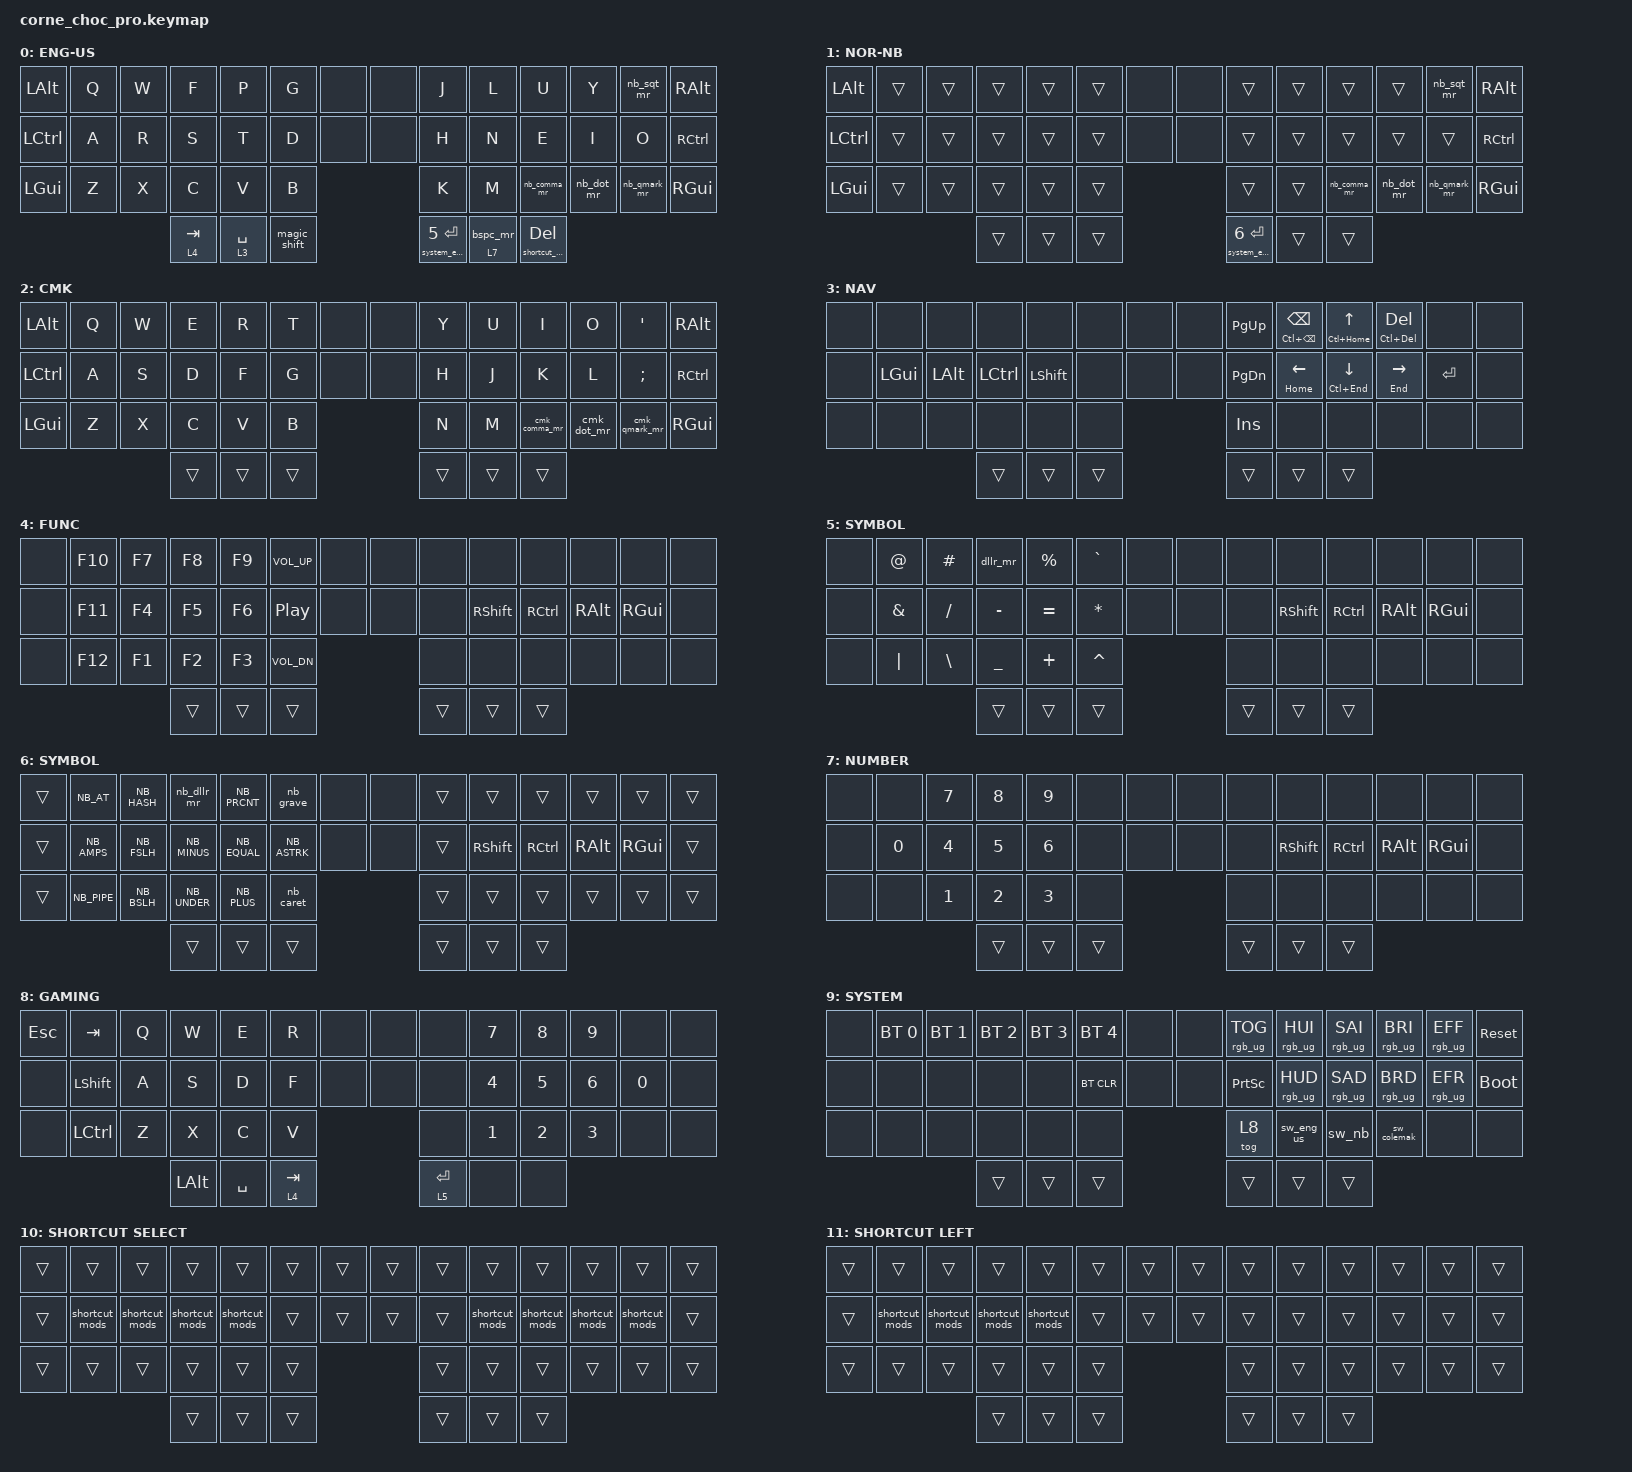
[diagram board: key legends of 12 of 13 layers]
/*
 * Copyright (c) 2020 The ZMK Contributors
 *
 * SPDX-License-Identifier: MIT
 */

#include <behaviors.dtsi>
#include <dt-bindings/zmk/keys.h>
#include <dt-bindings/zmk/bt.h>
#include <dt-bindings/zmk/rgb.h>

#include <behaviors/unicode.dtsi>  // Source header for this module
#include <zmk-helpers/helper.h>
#include <locale/keys_nb.h>

/* Corne Choc Pro 46-key position map (encoder buttons at 6, 7, 20, 21)
 * ╭───────────────────────────────╮ ╭───────────────────────────────╮
 * │ [0]   1   2   3   4   5  [6]  │ │  [7]  8   9  10  11  12  [13] │
 * │ [14] 15  16  17  18  19  [20] │ │ [21] 22  23  24  25  26  [27] │
 * │ [28] 29  30  31  32  33       │ │      34  35  36  37  38  [39] │
 * ╰────────────────╮ 40  41  42   │ │      43  44  45 ╭─────────────╯
 *                  ╰──────────────╯ ╰─────────────────╯              */
#define XXX &none
#define ___ &trans

/* Thumb layer-tap: hold = momentary layer, tap = keypress */
ZMK_HOLD_TAP(tlt,
    flavor = "balanced";
    tapping-term-ms = <200>;
    quick-tap-ms = <175>;
    bindings = <&mo>, <&kp>;
)

/* Thumb layer-tap for backspace: hold = momentary layer, tap = bspc/del mod-morph */
ZMK_HOLD_TAP(tlt_bspc,
    flavor = "balanced";
    tapping-term-ms = <200>;
    quick-tap-ms = <175>;
    bindings = <&mo>, <&bspc_mr>;
)

/* Nav mod-tap: hold = navigation shortcut, tap = key, double-tap+hold = repeat */
ZMK_HOLD_TAP(nav_mt,
    flavor = "tap-preferred";
    tapping-term-ms = <200>;
    quick-tap-ms = <175>;
    bindings = <&kp>, <&kp>;
)

/* Tap Delete; hold to select a hand for home-row shortcut modifiers. */
ZMK_HOLD_TAP(delete_shortcuts,
    flavor = "hold-preferred";
    tapping-term-ms = <200>;
    bindings = <&shortcut_mods>, <&kp>;
)

// Switch to using to shift instead of holding it down to get the alt buttons (mod morph)
#define NAV_LEFT  &nav_mt HOME     LEFT  // Tap: left  | Long-tap: start of line.
#define NAV_RIGHT &nav_mt END      RIGHT // Tap: right | Long-tap: end   of line.
#define NAV_UP    &nav_mt LC(HOME) UP    // Tap: up    | Long-tap: start of doc.
#define NAV_DOWN  &nav_mt LC(END)  DOWN  // Tap: down  | Long-tap: end   of doc.
#define NAV_BSPC  &nav_mt LC(BSPC) BSPC  // Tap: bspc  | Long-tap: delete word bwd.
#define NAV_DEL   &nav_mt LC(DEL)  DEL   // Tap: del   | Long-tap: delete word fwd.

/* Backspace / Delete mod-morph: tap = Bspc, Shift + tap = Del */
ZMK_MOD_MORPH(bspc_mr,
    bindings = <&kp BSPC>, <&kp DEL>;
    mods = <(MOD_LSFT|MOD_RSFT)>;
)

/* Norwegian mod-morphs: same semantics as US versions but with NB_ keycodes */
ZMK_MOD_MORPH(nb_comma_mr,
    bindings = <&kp NB_COMMA>, <&kp NB_SEMI>;
    mods = <(MOD_LSFT|MOD_RSFT)>;
)
ZMK_MOD_MORPH(nb_dot_mr,
    bindings = <&kp NB_DOT>, <&kp NB_COLON>;
    mods = <(MOD_LSFT|MOD_RSFT)>;
)
ZMK_MOD_MORPH(nb_qmark_mr,
    bindings = <&kp NB_QMARK>, <&kp NB_EXCL>;
    mods = <(MOD_LSFT|MOD_RSFT)>;
)
ZMK_MOD_MORPH(nb_dllr_mr,
    bindings = <&kp NB_DLLR>, <&kp NB_EURO>;
    mods = <(MOD_LSFT|MOD_RSFT)>;
)
ZMK_MOD_MORPH(nb_sqt_mr,
    bindings = <&kp NB_SQT>, <&kp NB_DQT>;
    mods = <(MOD_LSFT|MOD_RSFT)>;
)

/* Colemak maps P to ; and SEMI to O, so use the host-layout key positions. */
ZMK_MOD_MORPH(cmk_comma_mr,
    bindings = <&kp COMMA>, <&kp P>;
    mods = <(MOD_LSFT|MOD_RSFT)>;
)
ZMK_MOD_MORPH(cmk_dot_mr,
    bindings = <&kp DOT>, <&kp LS(P)>;
    mods = <(MOD_LSFT|MOD_RSFT)>;
)
ZMK_MOD_MORPH(cmk_qmark_mr,
    bindings = <&kp LS(SLASH)>, <&kp EXCL>;
    mods = <(MOD_LSFT|MOD_RSFT)>;
)
/* Dead keys: send dead key + space so Windows outputs the literal character */
ZMK_MACRO(nb_grave,
    bindings = <&kp NB_GRAVE &kp SPACE>;
)
ZMK_MACRO(nb_caret,
    bindings = <&kp NB_CARET &kp SPACE>;
)

/* Euro sign via Windows Alt+numpad (Alt+0128) — works without WinCompose */
ZMK_MACRO(euro,
    bindings
        = <&macro_press &kp LALT>
        , <&macro_tap &kp KP_N0>
        , <&macro_tap &kp KP_N1>
        , <&macro_tap &kp KP_N2>
        , <&macro_tap &kp KP_N8>
        , <&macro_release &kp LALT>;
)

/* Layout switch macros — &to 0 clears all overlays, then &tog N activates the desired overlay */
ZMK_MACRO(sw_eng_us, bindings = <&to 0>;)
ZMK_MACRO(sw_nb,      bindings = <&to 0 &tog 1>;)
ZMK_MACRO(sw_colemak, bindings = <&to 0 &tog 2>;)

/* Dollar / Euro mod-morph: tap = $, Shift + tap = € */
ZMK_MOD_MORPH(dllr_mr,
    bindings = <&kp DLLR>, <&euro>;
    mods = <(MOD_LSFT|MOD_RSFT)>;
)

/ {
    chosen {
        zmk,physical-layout = &default_layout;
    };
};

/ {
    behaviors {
        /* Tap = one-shot Shift, hold = Shift, double-tap = Caps Lock. */
        magic_shift: magic_shift {
            compatible = "zmk,behavior-magic-shift";
            #binding-cells = <0>;
            hold-term-ms = <200>;
            double-tap-ms = <250>;
            one-shot-term-ms = <1000>;
            bindings = <&kp LSHFT>, <&kp CAPS>;
        };

        system_enter: system_enter {
            compatible = "zmk,behavior-system-enter";
            #binding-cells = <2>;
            bindings = <&mo>, <&kp>;
            system-layer = <&system_layer>;
            tapping-term-ms = <200>;
            system-chord-term-ms = <200>;
            first-non-thumb-position = <40>;
        };

        shortcut_mods: shortcut_mods {
            compatible = "zmk,behavior-shortcut-mods";
            #binding-cells = <0>;
            bindings = <&kp LGUI>, <&kp LALT>, <&kp LCTRL>, <&kp LSHFT>,
                       <&kp RSHFT>, <&kp RCTRL>, <&kp RALT>, <&kp RGUI>;
        };
    };
};

/ {
    combos {
        compatible = "zmk,combos";
        // Top-row adjacent pairs — positions from the 46-key map above
        // Left side:  2=W  3=F  4=P
        // Right side: 9=L  10=U  11=Y

        combo_esc  { timeout-ms = <50>; require-prior-idle-ms = <150>; key-positions = <1 2>;   bindings = <&kp ESC>; };

        combo_rbkt    { timeout-ms = <50>; require-prior-idle-ms = <150>; key-positions = <2 3>;   bindings = <&kp RBKT>;    layers = <0 2>; };
        combo_lbkt    { timeout-ms = <50>; require-prior-idle-ms = <150>; key-positions = <3 4>;   bindings = <&kp LBKT>;    layers = <0 2>; };
        combo_nb_rbkt { timeout-ms = <50>; require-prior-idle-ms = <150>; key-positions = <2 3>;   bindings = <&kp NB_RBKT>; layers = <1>; };
        combo_nb_lbkt { timeout-ms = <50>; require-prior-idle-ms = <150>; key-positions = <3 4>;   bindings = <&kp NB_LBKT>; layers = <1>; };
        
        combo_rbrc    { timeout-ms = <50>; require-prior-idle-ms = <150>; key-positions = <30 31>; bindings = <&kp RBRC>;    layers = <0 2>; };
        combo_lbrc    { timeout-ms = <50>; require-prior-idle-ms = <150>; key-positions = <31 32>; bindings = <&kp LBRC>;    layers = <0 2>; };
        combo_nb_rbrc { timeout-ms = <50>; require-prior-idle-ms = <150>; key-positions = <30 31>; bindings = <&kp NB_RBRC>; layers = <1>; };
        combo_nb_lbrc { timeout-ms = <50>; require-prior-idle-ms = <150>; key-positions = <31 32>; bindings = <&kp NB_LBRC>; layers = <1>; };
        
        combo_lpar    { timeout-ms = <50>; require-prior-idle-ms = <150>; key-positions = <9 10>;  bindings = <&kp LPAR>;    layers = <0 2>; };
        combo_rpar    { timeout-ms = <50>; require-prior-idle-ms = <150>; key-positions = <10 11>; bindings = <&kp RPAR>;    layers = <0 2>; };
        combo_nb_lpar { timeout-ms = <50>; require-prior-idle-ms = <150>; key-positions = <9 10>;  bindings = <&kp NB_LPAR>; layers = <1>; };
        combo_nb_rpar { timeout-ms = <50>; require-prior-idle-ms = <150>; key-positions = <10 11>; bindings = <&kp NB_RPAR>; layers = <1>; };
        
        combo_lt      { timeout-ms = <50>; require-prior-idle-ms = <150>; key-positions = <35 36>; bindings = <&kp LS(COMMA)>; layers = <0 2>; };
        combo_gt      { timeout-ms = <50>; require-prior-idle-ms = <150>; key-positions = <36 37>; bindings = <&kp LS(DOT)>;   layers = <0 2>; };
        combo_nb_lt   { timeout-ms = <50>; require-prior-idle-ms = <150>; key-positions = <35 36>; bindings = <&kp NB_LT>;   layers = <1>; };
        combo_nb_gt   { timeout-ms = <50>; require-prior-idle-ms = <150>; key-positions = <36 37>; bindings = <&kp NB_GT>;   layers = <1>; };
        
    };
};

/ {
    keymap {
        compatible = "zmk,keymap";

        colemak_layer {
            display-name = "ENG-US";
            bindings = <
            //╭─────────────┬─────────────┬─────────────┬─────────────┬─────────────┬─────────────╮         ╭─────────────┬─────────────┬─────────────┬─────────────┬─────────────┬─────────────╮
                &kp LALT      &kp Q         &kp W         &kp F         &kp P         &kp G         XXX XXX   &kp J         &kp L         &kp U         &kp Y         &nb_sqt_mr    &kp RALT
            //├─────────────┼─────────────┼─────────────┼─────────────┬─────────────┼─────────────┤         ├─────────────┬─────────────┼─────────────┼─────────────┼─────────────┼─────────────┤
                &kp LCTRL     &kp A         &kp R         &kp S         &kp T         &kp D         XXX XXX   &kp H         &kp N         &kp E         &kp I         &kp O         &kp RCTRL
            //├─────────────┼─────────────┼─────────────┼─────────────┬─────────────┼─────────────┤         ├─────────────┬─────────────┼─────────────┼─────────────┼─────────────┼─────────────┤
                &kp LGUI      &kp Z         &kp X         &kp C         &kp V         &kp B                   &kp K         &kp M         &nb_comma_mr  &nb_dot_mr    &nb_qmark_mr  &kp RGUI
            //╰─────────────┼─────────────┴─────────────┼─────────────┬─────────────┼─────────────┤         ├─────────────┬─────────────┼─────────────┼─────────────┴───────────────────────────╯
            //                                            MAGIC SHIFT   NAVIGATION    FUNCTION                SYMBOL        NUMBERS       DELETE
                                                          &tlt 4 TAB    &tlt 3 SPACE  &magic_shift          &system_enter 5 RET    &tlt_bspc 7 0 &delete_shortcuts 0 DEL
            //                                          ╰─────────────┴─────────────┴─────────────╯         ╰─────────────┴─────────────┴─────────────╯
            >;
        };

        // - NORWEGIAN OVERLAY LAYERS (below all momentary layers so they don't shadow the display name) ---------------------------------

        nb_layer {
            display-name = "NOR-NB";
            bindings = <
            //╭─────────────┬─────────────┬─────────────┬─────────────┬─────────────┬─────────────╮         ╭─────────────┬─────────────┬─────────────┬─────────────┬─────────────┬─────────────╮
                &kp LALT      ___          ___           ___           ___           ___           XXX XXX   ___           ___           ___           ___           &nb_sqt_mr    &kp RALT
            //├─────────────┼─────────────┼─────────────┼─────────────┬─────────────┼─────────────┤         ├─────────────┬─────────────┼─────────────┼─────────────┼─────────────┼─────────────┤
                &kp LCTRL     ___           ___           ___           ___           ___           XXX XXX   ___           ___           ___           ___           ___           &kp RCTRL
            //├─────────────┼─────────────┼─────────────┼─────────────┬─────────────┼─────────────┤         ├─────────────┬─────────────┼─────────────┼─────────────┼─────────────┼─────────────┤
                &kp LGUI      ___           ___           ___           ___           ___                     ___           ___           &nb_comma_mr  &nb_dot_mr    &nb_qmark_mr  &kp RGUI
            //╰─────────────┼─────────────┴─────────────┼─────────────┬─────────────┼─────────────┤         ├─────────────┬─────────────┼─────────────┼─────────────┴───────────────────────────╯
                                                          ___           ___           ___                     &system_enter 6 RET    ___           ___
            //                                          ╰─────────────┴─────────────┴─────────────╯         ╰─────────────┴─────────────┴─────────────╯
            >;
        };

        // - COLEMAK OVERLAY LAYERS (below all momentary layers so they don't shadow the display name) ---------------------------------

        colemak_alpha_layer {
            display-name = "CMK";
            bindings = <
            //╭─────────────┬─────────────┬─────────────┬─────────────┬─────────────┬─────────────╮         ╭─────────────┬─────────────┬─────────────┬─────────────┬─────────────┬─────────────╮
            //  ALT           Q             W             E             R             T                       Y             U             I             O             ' / "         ALT
                &kp LALT      &kp Q         &kp W         &kp E         &kp R         &kp T         XXX XXX   &kp Y         &kp U         &kp I         &kp O         &kp SQT       &kp RALT
            //├─────────────┼─────────────┼─────────────┼─────────────┬─────────────┼─────────────┤         ├─────────────┬─────────────┼─────────────┼─────────────┼─────────────┼─────────────┤
            //  CTRL          A             S             D             F             G                       H             J             K             L             o / O         CTRL
                &kp LCTRL     &kp A         &kp S         &kp D         &kp F         &kp G         XXX XXX   &kp H         &kp J         &kp K         &kp L         &kp SEMI      &kp RCTRL
            //├─────────────┼─────────────┼─────────────┼─────────────┬─────────────┼─────────────┤         ├─────────────┬─────────────┼─────────────┼─────────────┼─────────────┼─────────────┤
            //  GUI           Z             X             C             V             B                       N             M             ,/;           ./:           ?/!           GUI
                &kp LGUI      &kp Z         &kp X         &kp C         &kp V         &kp B                   &kp N         &kp M         &cmk_comma_mr &cmk_dot_mr   &cmk_qmark_mr &kp RGUI
            //╰─────────────┼─────────────┴─────────────┼─────────────┬─────────────┼─────────────┤         ├─────────────┬─────────────┼─────────────┼─────────────┴───────────────────────────╯
            //                                            (transparent — fall through to ENG-US layer)
                                                          ___           ___           ___                     ___           ___           ___
            //                                          ╰─────────────┴─────────────┴─────────────╯         ╰─────────────┴─────────────┴─────────────╯
            >;
        };

        // - RIGHT LAYERS -------------------------------------------------------------------------------------------------------------------------------------------------------------------------------

        nav_layer {
            display-name = "NAV";
            bindings = <
            //╭─────────────┬─────────────┬─────────────┬─────────────┬─────────────┬─────────────╮         ╭─────────────┬─────────────┬─────────────┬─────────────┬─────────────┬─────────────╮
                XXX           XXX           XXX           XXX           XXX           XXX           XXX XXX   &kp PG_UP     NAV_BSPC      NAV_UP        NAV_DEL       XXX           XXX   
            //├─────────────┼─────────────┼─────────────┼─────────────┬─────────────┼─────────────┤         ├─────────────┬─────────────┼─────────────┼─────────────┼─────────────┼─────────────┤
                XXX           &kp LGUI      &kp LALT      &kp LCTRL     &kp LSHFT     XXX           XXX XXX   &kp PG_DN     NAV_LEFT      NAV_DOWN      NAV_RIGHT     &kp RET       XXX   
            //├─────────────┼─────────────┼─────────────┼─────────────┬─────────────┼─────────────┤         ├─────────────┬─────────────┼─────────────┼─────────────┼─────────────┼─────────────┤
                XXX           XXX           XXX           XXX           XXX           XXX                     &kp INS       XXX           XXX           XXX           XXX           XXX   
            //╰─────────────┼─────────────┴─────────────┼─────────────┬─────────────┼─────────────┤         ├─────────────┬─────────────┼─────────────┼─────────────┴───────────────────────────╯
                                                          ___           ___           ___                     ___           ___           ___   
            //                                          ╰─────────────┴─────────────┴─────────────╯         ╰─────────────┴─────────────┴─────────────╯
            >;
        };

        func_layer {
            display-name = "FUNC"; 
            bindings = <
            //╭─────────────┬─────────────┬─────────────┬─────────────┬─────────────┬─────────────╮         ╭─────────────┬─────────────┬─────────────┬─────────────┬─────────────┬─────────────╮
                XXX           &kp F10       &kp F7        &kp F8        &kp F9        &kp C_VOL_UP  XXX XXX   XXX           XXX           XXX           XXX           XXX           XXX   
            //├─────────────┼─────────────┼─────────────┼─────────────┬─────────────┼─────────────┤         ├─────────────┬─────────────┼─────────────┼─────────────┼─────────────┼─────────────┤
                XXX           &kp F11       &kp F4        &kp F5        &kp F6        &kp C_PP      XXX XXX   XXX           &kp RSHFT     &kp RCTRL     &kp RALT      &kp RGUI      XXX   
            //├─────────────┼─────────────┼─────────────┼─────────────┬─────────────┼─────────────┤         ├─────────────┬─────────────┼─────────────┼─────────────┼─────────────┼─────────────┤
                XXX           &kp F12       &kp F1        &kp F2        &kp F3        &kp C_VOL_DN            XXX           XXX           XXX           XXX           XXX           XXX   
            //╰─────────────┼─────────────┴─────────────┼─────────────┬─────────────┼─────────────┤         ├─────────────┬─────────────┼─────────────┼─────────────┴───────────────────────────╯
                                                          ___           ___           ___                     ___           ___           ___   
            //                                          ╰─────────────┴─────────────┴─────────────╯         ╰─────────────┴─────────────┴─────────────╯
            >;
        };

        // - LEFT LAYERS --------------------------------------------------------------------------------------------------------------------------------------------------------------------------------
        
        symbol_layer {
            display-name = "SYMBOL";
            bindings = <
            //╭─────────────┬─────────────┬─────────────┬─────────────┬─────────────┬─────────────╮         ╭─────────────┬─────────────┬─────────────┬─────────────┬─────────────┬─────────────╮
                XXX           &kp AT        &kp HASH      &dllr_mr      &kp PRCNT     &kp GRAVE     XXX XXX   XXX           XXX           XXX           XXX           XXX           XXX   
            //├─────────────┼─────────────┼─────────────┼─────────────┬─────────────┼─────────────┤         ├─────────────┬─────────────┼─────────────┼─────────────┼─────────────┼─────────────┤
                XXX           &kp AMPS      &kp FSLH      &kp MINUS     &kp EQUAL     &kp ASTRK     XXX XXX   XXX           &kp RSHFT     &kp RCTRL     &kp RALT      &kp RGUI      XXX   
            //├─────────────┼─────────────┼─────────────┼─────────────┬─────────────┼─────────────┤         ├─────────────┬─────────────┼─────────────┼─────────────┼─────────────┼─────────────┤
                XXX           &kp PIPE      &kp BSLH      &kp UNDER     &kp PLUS      &kp CARET               XXX           XXX           XXX           XXX           XXX           XXX   
            //╰─────────────┼─────────────┴─────────────┼─────────────┬─────────────┼─────────────┤         ├─────────────┬─────────────┼─────────────┼─────────────┴───────────────────────────╯
                                                          ___           ___           ___                     ___           ___           ___   
            //                                          ╰─────────────┴─────────────┴─────────────╯         ╰─────────────┴─────────────┴─────────────╯
           >;
        };

        nb_sym_layer {
            display-name = "SYMBOL";
            bindings = <
            //╭─────────────┬─────────────┬─────────────┬─────────────┬─────────────┬─────────────╮         ╭─────────────┬─────────────┬─────────────┬─────────────┬─────────────┬─────────────╮
                ___           &kp NB_AT     &kp NB_HASH   &nb_dllr_mr   &kp NB_PRCNT  &nb_grave     XXX XXX   ___           ___           ___           ___           ___           ___
            //├─────────────┼─────────────┼─────────────┼─────────────┬─────────────┼─────────────┤         ├─────────────┬─────────────┼─────────────┼─────────────┼─────────────┼─────────────┤
                ___           &kp NB_AMPS   &kp NB_FSLH   &kp NB_MINUS  &kp NB_EQUAL  &kp NB_ASTRK  XXX XXX   ___           &kp RSHFT     &kp RCTRL     &kp RALT      &kp RGUI      ___
            //├─────────────┼─────────────┼─────────────┼─────────────┬─────────────┼─────────────┤         ├─────────────┬─────────────┼─────────────┼─────────────┼─────────────┼─────────────┤
                ___           &kp NB_PIPE   &kp NB_BSLH   &kp NB_UNDER  &kp NB_PLUS   &nb_caret               ___           ___           ___           ___           ___           ___
            //╰─────────────┼─────────────┴─────────────┼─────────────┬─────────────┼─────────────┤         ├─────────────┬─────────────┼─────────────┼─────────────┴───────────────────────────╯
                                                          ___           ___           ___                     ___           ___           ___
            //                                          ╰─────────────┴─────────────┴─────────────╯         ╰─────────────┴─────────────┴─────────────╯
            >;
        };

        number_layer {
            display-name = "NUMBER";
            bindings = <
            //╭─────────────┬─────────────┬─────────────┬─────────────┬─────────────┬─────────────╮         ╭─────────────┬─────────────┬─────────────┬─────────────┬─────────────┬─────────────╮
                XXX           XXX           &kp N7        &kp N8        &kp N9        XXX           XXX XXX   XXX           XXX           XXX           XXX           XXX           XXX   
            //├─────────────┼─────────────┼─────────────┼─────────────┬─────────────┼─────────────┤         ├─────────────┬─────────────┼─────────────┼─────────────┼─────────────┼─────────────┤
                XXX           &kp N0        &kp N4        &kp N5        &kp N6        XXX           XXX XXX   XXX           &kp RSHFT     &kp RCTRL     &kp RALT      &kp RGUI      XXX   
            //├─────────────┼─────────────┼─────────────┼─────────────┬─────────────┼─────────────┤         ├─────────────┬─────────────┼─────────────┼─────────────┼─────────────┼─────────────┤
                XXX           XXX           &kp N1        &kp N2        &kp N3        XXX                     XXX           XXX           XXX           XXX           XXX           XXX   
            //╰─────────────┼─────────────┴─────────────┼─────────────┬─────────────┼─────────────┤         ├─────────────┬─────────────┼─────────────┼─────────────┴───────────────────────────╯
                                                          ___           ___           ___                     ___           ___           ___   
            //                                          ╰─────────────┴─────────────┴─────────────╯         ╰─────────────┴─────────────┴─────────────╯
            >;
        };

        // - MULTY SIDE LAYERS --------------------------------------------------------------------------------------------------------------------------------------------------------------------------
        
        gaming_layer {
            display-name = "GAMING";
            bindings = <
            //╭─────────────┬─────────────┬─────────────┬─────────────┬─────────────┬─────────────╮         ╭─────────────┬─────────────┬─────────────┬─────────────┬─────────────┬─────────────╮
                &kp ESC       &kp TAB       &kp Q         &kp W         &kp E         &kp R         XXX XXX   XXX           &kp N7        &kp N8        &kp N9        XXX           XXX  
            //├─────────────┼─────────────┼─────────────┼─────────────┬─────────────┼─────────────┤         ├─────────────┬─────────────┼─────────────┼─────────────┼─────────────┼─────────────┤
                XXX           &kp LSHFT     &kp A         &kp S         &kp D         &kp F         XXX XXX   XXX           &kp N4        &kp N5        &kp N6        &kp N0        XXX
            //├─────────────┼─────────────┼─────────────┼─────────────┬─────────────┼─────────────┤         ├─────────────┬─────────────┼─────────────┼─────────────┼─────────────┼─────────────┤
                XXX           &kp LCTRL     &kp Z         &kp X         &kp C         &kp V                   XXX           &kp N1        &kp N2        &kp N3        XXX           XXX  
            //╰─────────────┼─────────────┴─────────────┼─────────────┬─────────────┼─────────────┤         ├─────────────┬─────────────┼─────────────┼─────────────┴───────────────────────────╯
            //                                            ALT           NAVIGATION    SYMBOL                  MEDIA
                                                          &kp LALT       &kp SPACE     &tlt 4 TAB              &tlt 5 RET    XXX           XXX
            //                                          ╰─────────────┴─────────────┴─────────────╯         ╰─────────────┴─────────────┴─────────────╯
            >;
        };

        system_layer: system_layer {
            display-name = "SYSTEM";
            bindings = <
            //╭─────────────┬─────────────┬─────────────┬─────────────┬─────────────┬─────────────╮         ╭────────────────┬────────────────┬────────────────┬────────────────┬────────────────┬─────────────╮
            //                BT profile 0  BT profile 1  BT profile 2  BT profile 3  BT profile 4            RGB toggle       Hue +            Saturation +     Brightness +     Effect fwd
                XXX           &bt BT_SEL 0  &bt BT_SEL 1  &bt BT_SEL 2  &bt BT_SEL 3  &bt BT_SEL 4  XXX XXX   &rgb_ug RGB_TOG  &rgb_ug RGB_HUI  &rgb_ug RGB_SAI  &rgb_ug RGB_BRI  &rgb_ug RGB_EFF  &sys_reset                                             
            //├─────────────┼─────────────┼─────────────┼─────────────┬─────────────┼─────────────┤         ├────────────────┼────────────────┼────────────────┬────────────────┼────────────────┼─────────────┤
            //                                                                        BT clear                                 NOR-NB Hue -     Saturation -     Brightness -     Effect back
                XXX           XXX           XXX           XXX           XXX           &bt BT_CLR    XXX XXX   &kp PRINTSCREEN  &rgb_ug RGB_HUD  &rgb_ug RGB_SAD  &rgb_ug RGB_BRD  &rgb_ug RGB_EFR  &bootloader
            //├─────────────┼─────────────┼─────────────┼─────────────┬─────────────┼─────────────┤         ├────────────────┼────────────────┼────────────────┬────────────────┼────────────────┼─────────────┤
            //                                                                                                Toggle gaming    ENG-US           NOR-NB           COLEMAK  
                XXX           XXX           XXX           XXX           XXX           XXX                     &tog 8           &sw_eng_us       &sw_nb           &sw_colemak           XXX              XXX
            //╰─────────────┼─────────────┴─────────────┼─────────────┬─────────────┼─────────────┤         ├────────────────┼────────────────┼────────────────┼────────────────┴────────────────┴─────────────╯
                                                          ___           ___           ___                     ___              ___              ___
            //                                          ╰─────────────┴─────────────┴─────────────╯         ╰────────────────┴────────────────┴────────────────╯
            >;
        };

        shortcut_select_layer: shortcut_select_layer {
            display-name = "SHORTCUT SELECT";
            bindings = <
                ___           ___           ___           ___           ___           ___           ___ ___   ___           ___           ___           ___           ___           ___
                ___           &shortcut_mods &shortcut_mods &shortcut_mods &shortcut_mods ___      ___ ___   ___           &shortcut_mods &shortcut_mods &shortcut_mods &shortcut_mods ___
                ___           ___           ___           ___           ___           ___                     ___           ___           ___           ___           ___           ___
                ___           ___           ___                     ___           ___           ___
            >;
        };

        shortcut_left_layer: shortcut_left_layer {
            display-name = "SHORTCUT LEFT";
            bindings = <
                ___           ___           ___           ___           ___           ___           ___ ___   ___           ___           ___           ___           ___           ___
                ___           &shortcut_mods &shortcut_mods &shortcut_mods &shortcut_mods ___      ___ ___   ___           ___           ___           ___           ___           ___
                ___           ___           ___           ___           ___           ___                     ___           ___           ___           ___           ___           ___
                ___           ___           ___                     ___           ___           ___
            >;
        };

        shortcut_right_layer: shortcut_right_layer {
            display-name = "SHORTCUT RIGHT";
            bindings = <
                ___           ___           ___           ___           ___           ___           ___ ___   ___           ___           ___           ___           ___           ___
                ___           ___           ___           ___           ___           ___           ___ ___   ___           &shortcut_mods &shortcut_mods &shortcut_mods &shortcut_mods ___
                ___           ___           ___           ___           ___           ___                     ___           ___           ___           ___           ___           ___
                ___           ___           ___                     ___           ___           ___
            >;
        };
    };
};
